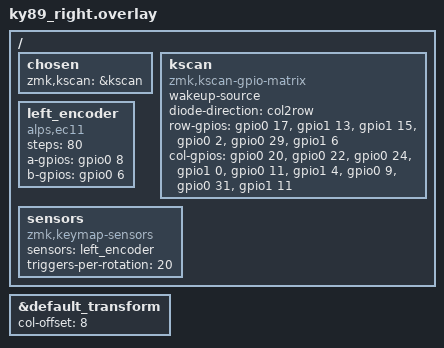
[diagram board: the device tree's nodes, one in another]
/*
 * Copyright (c) 2023 The ZMK Contributors
 *
 * SPDX-License-Identifier: MIT
 */

#include "ky89.dtsi"
/ {
    chosen {
        zmk,kscan = &kscan;
    };

    kscan: kscan {
        compatible = "zmk,kscan-gpio-matrix";
        wakeup-source;

        diode-direction = "col2row";

        row-gpios
            = <&gpio0 17 (GPIO_PULL_DOWN | GPIO_ACTIVE_HIGH)>
            , <&gpio1 13 (GPIO_PULL_DOWN | GPIO_ACTIVE_HIGH)>
            , <&gpio1 15 (GPIO_PULL_DOWN | GPIO_ACTIVE_HIGH)>
            , <&gpio0  2 (GPIO_PULL_DOWN | GPIO_ACTIVE_HIGH)>
            , <&gpio0 29 (GPIO_PULL_DOWN | GPIO_ACTIVE_HIGH)>
            , <&gpio1  6 (GPIO_PULL_DOWN | GPIO_ACTIVE_HIGH)>
            ;

        col-gpios
            = <&gpio0 20 GPIO_ACTIVE_HIGH>
            , <&gpio0 22 GPIO_ACTIVE_HIGH>
            , <&gpio0 24 GPIO_ACTIVE_HIGH>
            , <&gpio1  0 GPIO_ACTIVE_HIGH>
            , <&gpio0 11 GPIO_ACTIVE_HIGH>
            , <&gpio1  4 GPIO_ACTIVE_HIGH>
            , <&gpio0  9 GPIO_ACTIVE_HIGH>
            , <&gpio0 31 GPIO_ACTIVE_HIGH>
            , <&gpio1 11 GPIO_ACTIVE_HIGH>
            ;
    };

    left_encoder: left_encoder {
        compatible = "alps,ec11";
        steps = <80>;
        a-gpios = <&gpio0  8 (GPIO_ACTIVE_HIGH | GPIO_PULL_UP)>;
        b-gpios = <&gpio0  6 (GPIO_ACTIVE_HIGH | GPIO_PULL_UP)>;
        status = "okay";
    };
 
    sensors: sensors {
        compatible = "zmk,keymap-sensors";
        //sensors = <&left_encoder1 &right_encoder1>;
        sensors = <&left_encoder>;
        triggers-per-rotation = <20>;
    };
};

&default_transform {
    col-offset = <8>;
};

